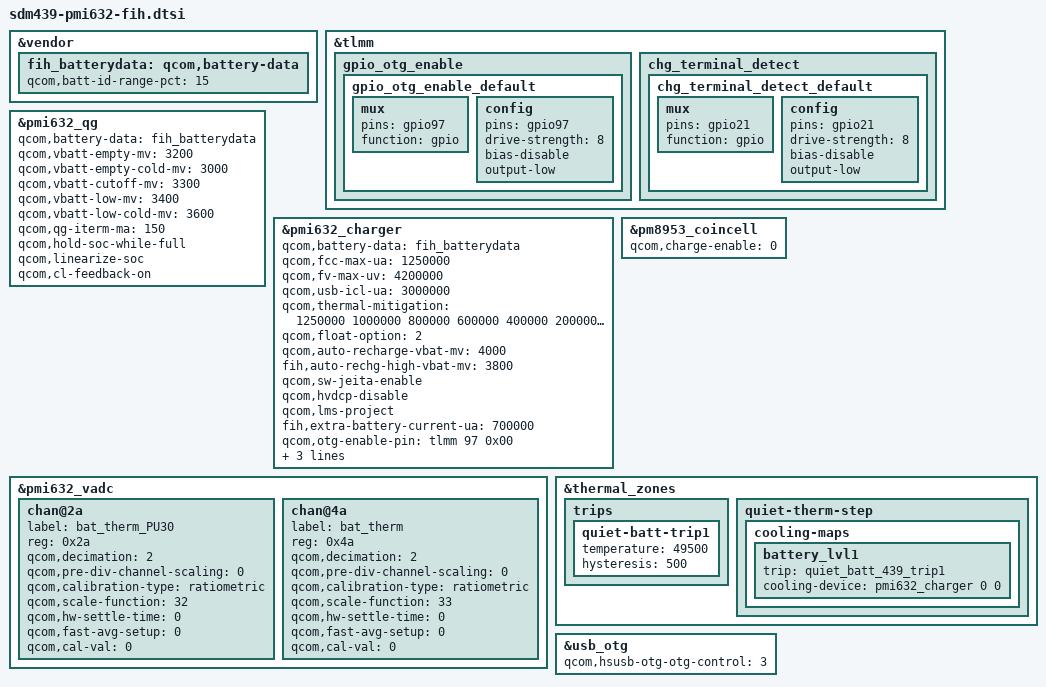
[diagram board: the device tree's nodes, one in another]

&vendor {
	fih_batterydata: qcom,battery-data {
		qcom,batt-id-range-pct = <15>;
		#include "qg-batterydata-lms-fake-1900mah_200k.dtsi"
		#include "qg-batterydata-lms-584455pl-1900mah-100k.dtsi"
	};
};

&tlmm {
	gpio_otg_enable {
		gpio_otg_enable_default: gpio_otg_enable_default {
			mux {
				pins = "gpio97";
				function = "gpio";
			};
			config {
				pins = "gpio97";
				drive-strength = <8>;
				bias-disable;
				output-low;
			};
		};
	};
	chg_terminal_detect {
		chg_terminal_detect_default: chg_terminal_detect_default {
			mux {
				pins = "gpio21";
				function = "gpio";
			};
			config {
				pins = "gpio21";
				drive-strength = <8>;
				bias-disable;
				output-low;
			};
		};
	};
};


&pmi632_qg {
	qcom,battery-data = <&fih_batterydata>;
	qcom,vbatt-empty-mv = <3200>;
	qcom,vbatt-empty-cold-mv = <3000>;
	qcom,vbatt-cutoff-mv = <3300>;
	qcom,vbatt-low-mv = <3400>;
	qcom,vbatt-low-cold-mv = <3600>;
	qcom,qg-iterm-ma = <150>;
	qcom,hold-soc-while-full;
	qcom,linearize-soc;
	qcom,cl-feedback-on;
};

&pmi632_charger {
	qcom,battery-data = <&fih_batterydata>;
	qcom,fcc-max-ua = <1250000>; // not common settings, set in project dtsi
	qcom,fv-max-uv = <4200000>;
	qcom,usb-icl-ua = <3000000>;
	qcom,thermal-mitigation = <1250000 1000000 800000 600000 400000 200000 0>;
	qcom,float-option = <2>;
	//qcom,auto-recharge-soc = <90>;
	qcom,auto-recharge-vbat-mv = <4000>;
	fih,auto-rechg-high-vbat-mv = <3800>;
	qcom,sw-jeita-enable;
	qcom,hvdcp-disable;
	qcom,lms-project;
	fih,extra-battery-current-ua = <700000>;
	qcom,otg-enable-pin = <&tlmm 97 0x00>; //set low to charge, set hight to otg
	qcom,chg-terminal-pin = <&tlmm 21 0x00>;
	pinctrl-names = "default";
	pinctrl-0 = <&gpio_otg_enable_default &chg_terminal_detect_default>;
};

//&pm8953_typec {
//	status = "disabled";
//};

&pmi632_vadc {
	chan@2a {
		label = "bat_therm_PU30";
		reg = <0x2a>;
		qcom,decimation = <2>;
		qcom,pre-div-channel-scaling = <0>;
		qcom,calibration-type = "ratiometric";
		qcom,scale-function = <32>;   // SCALE_BATT_THERM_FIH_B3435_10K_OD6 = 32 in qpnp-adc.h
		qcom,hw-settle-time = <0>;
		qcom,fast-avg-setup = <0>;
		qcom,cal-val = <0>;
	};
	chan@4a {
		label = "bat_therm";
		reg = <0x4a>;
		qcom,decimation = <2>;
		qcom,pre-div-channel-scaling = <0>;
		qcom,calibration-type = "ratiometric";
		qcom,scale-function = <33>;		// SCALE_BATT_THERM_FIH_B4250_100K_OD6 = 33 in qpnp-adc.h
		qcom,hw-settle-time = <0>;
		qcom,fast-avg-setup = <0>;
		qcom,cal-val = <0>;
	};
};

&pm8953_coincell {
	qcom,charge-enable = <0>;
};

&thermal_zones {
  trips {
    quiet-batt-trip1 {
    		temperature = <49500>;
				hysteresis = <500>;
			};
  };

  quiet-therm-step {
    cooling-maps {
      battery_lvl1 {
				trip = <&quiet_batt_439_trip1>;
				cooling-device = <&pmi632_charger 0 0>;
			};
    };
  };
};
&usb_otg {
	qcom,hsusb-otg-otg-control = <3>; /* PMIC */
};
